# A31G21x register map
Vendor: ABOV Semiconductor Co., Ltd.; Series: A31G21x; File version: 1.0
CPU: CM0PLUS r0p1, little endian, no MPU, no FPU, VTOR, 2 interrupt priority bits
Registers are 32-bit, read-write, reset 0x0 unless marked. A register's access mark holds for its fields unless they carry their own. Offsets are from the block's base; [hi:lo] are bit positions; {n}, {i} and the like mark numbered series.

## ADC — 12-BIT A/D CONVERTER
Base 0x40003000
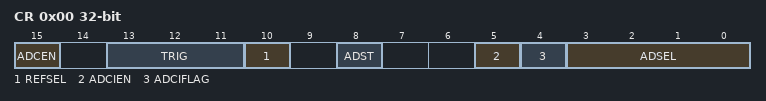
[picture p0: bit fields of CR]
0x00 CR — A/D Converter Control Register
  [15] ADCEN — A/DC Module Enable bit (The A/DC is automatically disabled at power down mode)
    0=DISABLE_ADC (Disable A/DC module operation); 1=ENABLE_ADC (Enable A/DC module operation)
  [13:11] TRIG — A/DC Trigger Signal Selection bits
    0=ADST; 1=T10_A_MATCH (Timer 10 A-match signal); 2=T11_A_MATCH (Timer 11 A-match signal); 3=T12_A_MATCH (Timer 12 A-match signal); 4=T30_SIGNAL (A/DC trigger signal from timer 30)
  [10] REFSEL — A/DC Reference Selection bit
    0=VDD (Select analog power (VDD)); 1=AVREF (Select external reference (AVREF))
  [8] ADST — A/DC Conversion Start bit. This bit is automatically cleared to "0b" after operation
    0=NONE (No effect); 1=START_AD_CONVERSION (Trigger signal generation for conversion start)
  [5] ADCIEN — A/DC Interrupt Enable bit
    0=DISABLE_ADC_INT (Disable A/DC interrupt); 1=ENABLE_ADC_INT (Enable A/DC interrupt)
  [4] ADCIFLAG — A/DC Interrupt Flag bit
    0=ADC_IF_CLR (No request occurred); 1=ADC_IF_SET (Request occurred, This bit is cleared to '0' when write '1'.)
  [3:0] ADSEL — A/D Converter Channel Selection bits
    {v}=AN{v} (v=0..10); 15=VDD18 (VDD15)
0x04 DR ro — A/D Converter Data Register
  [11:0] ADDATA — A/D Converter Result Data bits
0x08 PREDR reset 0xF — A/D Converter Prescaler Data Register
  [4:0] PRED — A/D Converter Prescaler Data bits.

## DAC — 5-BIT D/A CONVERTER
Base 0x40003450
0x00 CR — D/A Converter Control Register
  [0] DACEN — D/A Converter Enable Bit
0x04 DR — D/A Converter Buffer Register
  [11:4] DADTA ro — D/A Converter Data Data The DADATA[11:4] is a binary format.
0x08 DACEN — D/A Converter Control TEST Register
  [0] DACPORT — D/A output Enable Bit

## LED — LED DRIVER/CONTROLLER
Base 0x40006000
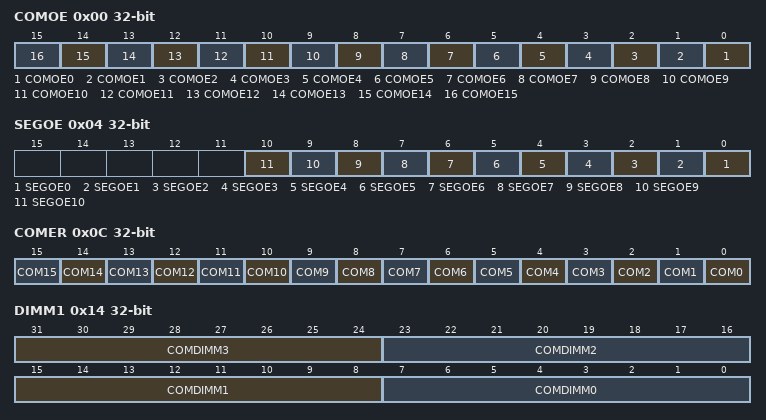
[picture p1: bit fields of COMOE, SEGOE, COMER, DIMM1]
0x00 COMOE — COM Output Enable Register
  [n] COMOE{n} (n=0..15) — COM{n} Port Mode Selection
0x04 SEGOE — SEG Output Enable Register
  [n] SEGOE{n} (n=0..10) — SEG{n} Port Mode Selection
0x08 PRESD — LED Prescaler Data Register
  [15:0] PRESD — Pre-scale value of LED clock LED Clock = fCLK/(PRESD + 1) (fCLK is a selected input clock)
0x0C COMER — COM EnableRegister
  [n] COM{n} (n=0..15) — Only Selected COM{n} is active.
0x10 COMPWID — COM Pulse Width Control Register
  [7:0] COMPWID — COM Pulse Width Control bits COM Width= LED CLK/(COMPWID + 1) (LED CLK is Prescaler output clock)
0x14 DIMM1 — COM Dimming Control Register1
  [31:24] COMDIMM3 — COM3 Dimming Control bits Dimmed COM Width = COM Width - Overlaptime - LEDCLK*COMDIMM3
  [23:16] COMDIMM2 — COM2 Dimming Control bits Dimmed COM Width = COM Width - Overlaptime- LEDCLK*COMDIMM2
  [15:8] COMDIMM1 — COM1 Dimming Control bits Dimmed COM Width = COM Width - Overlaptime - LEDCLK*COMDIMM1
  [7:0] COMDIMM0 — COM0 Dimming Control bits Dimmed COM Width = COM Width - Overlaptime - LEDCLK*COMDIMM0
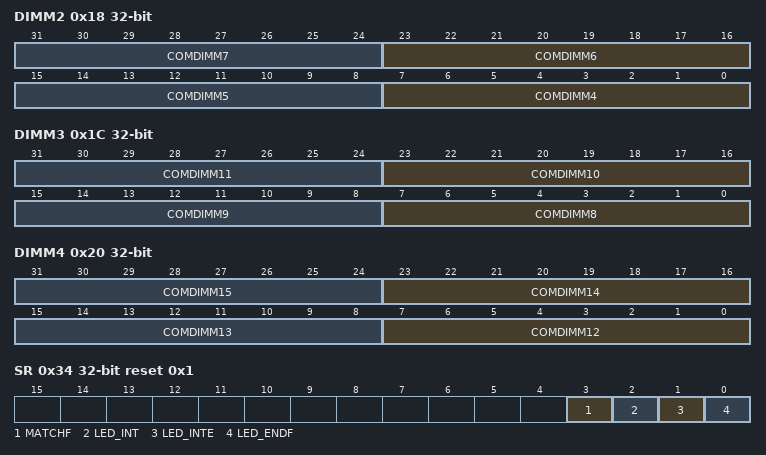
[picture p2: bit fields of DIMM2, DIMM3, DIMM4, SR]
0x18 DIMM2 — COM Dimming Control Register2
  [8n-25:8n-32] COMDIMM{n} (n=4..7) — COM{n} Dimming Control bits Dimmed COM Width = COM Width - Overlaptime - LEDCLK*COMDIMM{n}
0x1C DIMM3 — COM Dimming Control Register3
  [8n-57:8n-64] COMDIMM{n} (n=8..11) — COM{n} Dimming Control bits Dimmed COM Width = COM Width - Overlaptime - LEDCLK*COMDIMM{n}
0x20 DIMM4 — COM Dimming Control Register4
  [8n-89:8n-96] COMDIMM{n} (n=12..15) — COM{n} Dimming Control bits Dimmed COM Width = COM Width - Overlaptime - LEDCLK*COMDIMM{n}
0x30 STPD — LED STOP Duration Register
  [19:0] LEDSTPD — LED STOP Duration Register (since LED Start)
0x34 SR reset 0x1 — LED STATUS Register
  [3] MATCHF — Flag to occur when LEDSTPD reg match with counter
  [2] LED_INT — LED Interrupt Flag(in LED_INTE=1)
  [1] LED_INTE — LED Interrupt Enable
  [0] LED_ENDF — LED Operation End Flag
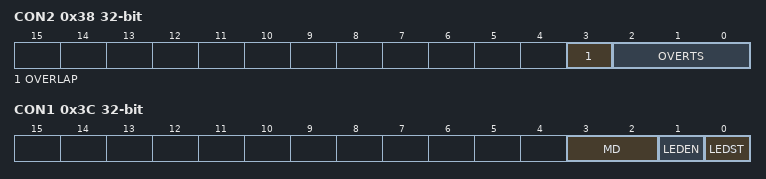
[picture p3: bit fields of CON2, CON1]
0x38 CON2 — LED Control Register2
  [3] OVERLAP — OVERLAP TIME Select
  [2:0] OVERTS — OVERLAP TIME Select
0x3C CON1 — LED Control Register1
  [3:2] MD — Mode Select
  [1] LEDEN — LED Enable
  [0] LEDST — LED START, STOP Operation
{0x44+4i} DISPRAM{i} (i=0..15) — LED Display data {i}

## CRC — CYCLIC REDUNDANCY CHECK AND CHECKSUM
Base 0x40000300
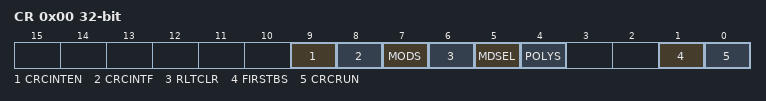
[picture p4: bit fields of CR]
0x00 CR — CRC/Checksum Control Register. Notes: 1. The CRCRLT register and the CRC/Checksum block should be initialized by writing "1b" to the RLTCLR bit before a new CRC/Checksum calculation. 2. The CRCRUN bit should be set to "1b" last time after setting appropriate values to the registers. 3. On the user mode, it will be calculated every writing data to the CRCIN register during CRCRUN==1. 4. On the user mode with SARINC==0, the block is finished by writing "0b" to the CRCRUN bit. 4. It is prohibited writing any data to the CRCIN register during CRCRUN==0. 5. The checksum is calculated by byte unit. Ex) On 0x34A7E991, CRCRLT = 0x34 + 0xA7 + 0xE9 + 0x91.
  [9] CRCINTEN — CRC interrupt enable bit
  [8] CRCINTF — CRC interrupt flag bit
  [7] MODS — User/Auto Mode Selection bit
  [6] RLTCLR — CRC/Checksum Result Data Register (CRCRLT) Initialization bit
  [5] MDSEL — CRC/Checksum Selection bit
  [4] POLYS — Polynomial Selection bit (CRC only)
  [1] FIRSTBS — First Shifted-in Selection bit (CRC only)
  [0] CRCRUN — CRC/Checksum Start Control and Busy bit
0x04 IN — CRC/Checksum Input Data Register
  [31:0] INDATA — CRC Input Data bit
0x08 RLT ro reset 0xFFFF — CRC/Checksum Result Data Register
  [15:0] RLTDATA rw — CRC Result Data bit
0x0C INIT — CRC/Checksum Initial Data Register
  [15:0] INIDATA — CRC Initial Data bit
